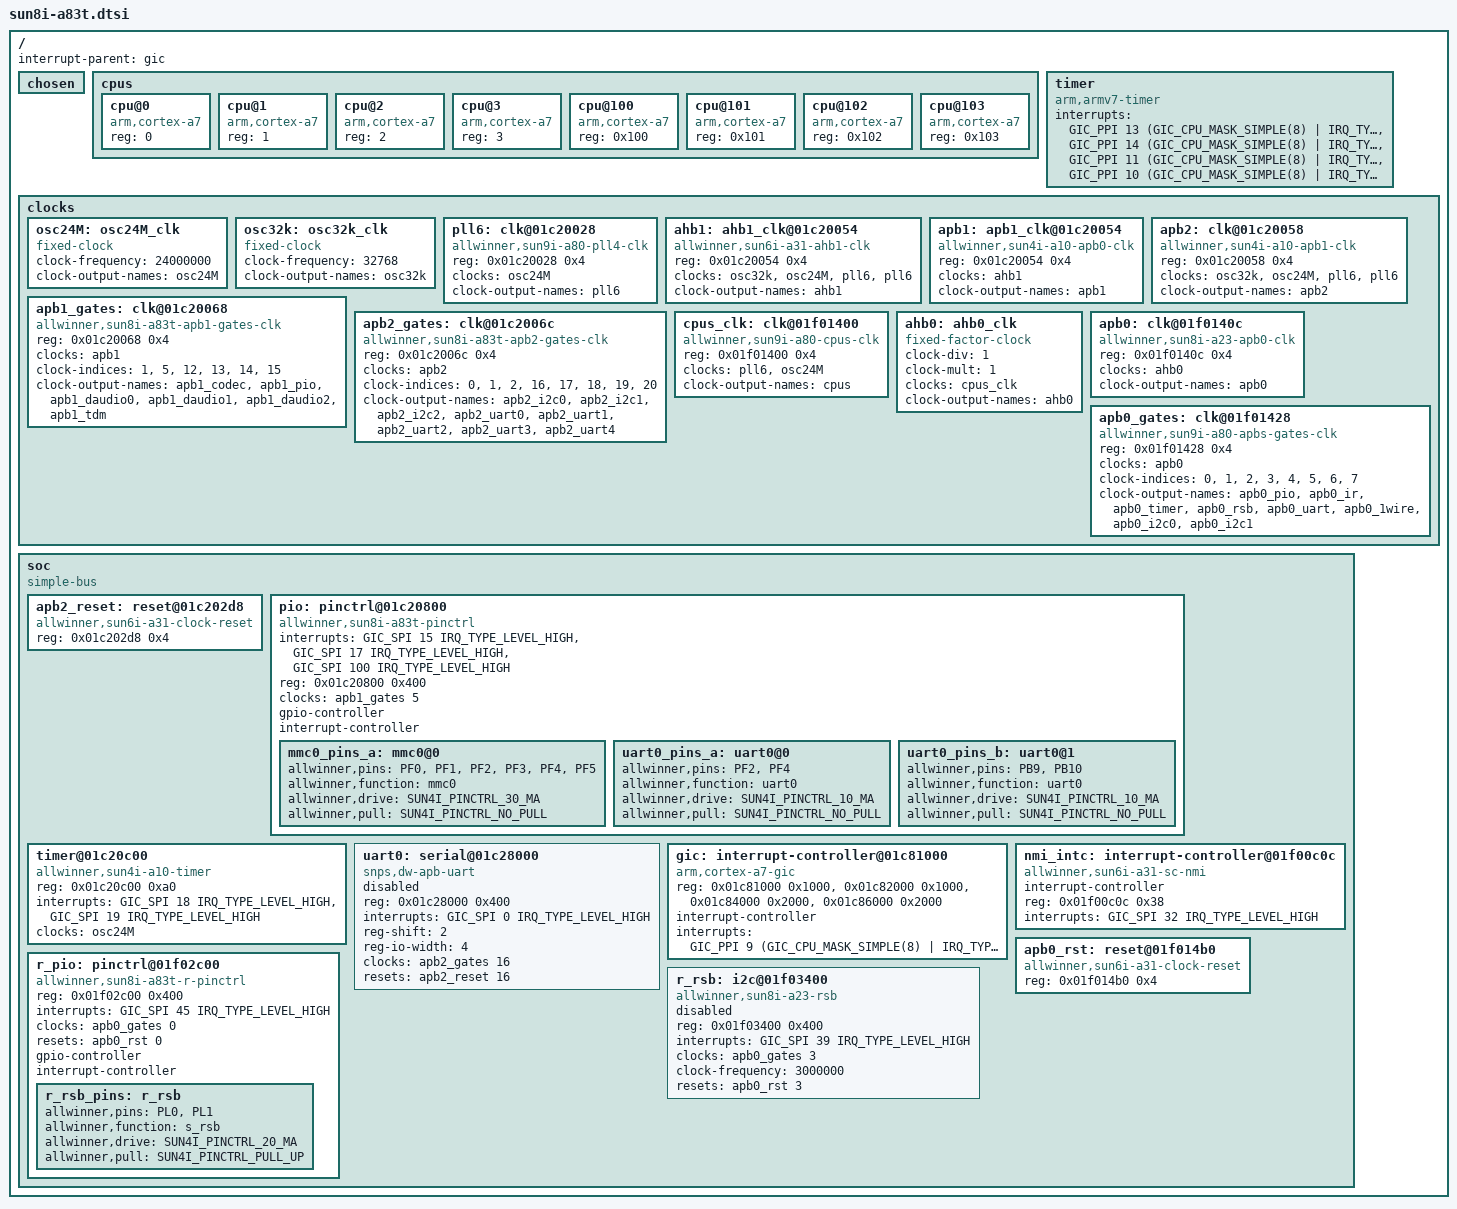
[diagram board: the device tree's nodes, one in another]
/*
 * Copyright 2015 Vishnu Patekar
 *
 * Vishnu Patekar <vishnupatekar0510@gmail.com>
 *
 * This file is dual-licensed: you can use it either under the terms
 * of the GPL or the X11 license, at your option. Note that this dual
 * licensing only applies to this file, and not this project as a
 * whole.
 *
 *  a) This file is free software; you can redistribute it and/or
 *     modify it under the terms of the GNU General Public License as
 *     published by the Free Software Foundation; either version 2 of the
 *     License, or (at your option) any later version.
 *
 *     This file is distributed in the hope that it will be useful,
 *     but WITHOUT ANY WARRANTY; without even the implied warranty of
 *     MERCHANTABILITY or FITNESS FOR A PARTICULAR PURPOSE.  See the
 *     GNU General Public License for more details.
 *
 * Or, alternatively,
 *
 *  b) Permission is hereby granted, free of charge, to any person
 *     obtaining a copy of this software and associated documentation
 *     files (the "Software"), to deal in the Software without
 *     restriction, including without limitation the rights to use,
 *     copy, modify, merge, publish, distribute, sublicense, and/or
 *     sell copies of the Software, and to permit persons to whom the
 *     Software is furnished to do so, subject to the following
 *     conditions:
 *
 *     The above copyright notice and this permission notice shall be
 *     included in all copies or substantial portions of the Software.
 *
 *     THE SOFTWARE IS PROVIDED "AS IS", WITHOUT WARRANTY OF ANY KIND,
 *     EXPRESS OR IMPLIED, INCLUDING BUT NOT LIMITED TO THE WARRANTIES
 *     OF MERCHANTABILITY, FITNESS FOR A PARTICULAR PURPOSE AND
 *     NONINFRINGEMENT. IN NO EVENT SHALL THE AUTHORS OR COPYRIGHT
 *     HOLDERS BE LIABLE FOR ANY CLAIM, DAMAGES OR OTHER LIABILITY,
 *     WHETHER IN AN ACTION OF CONTRACT, TORT OR OTHERWISE, ARISING
 *     FROM, OUT OF OR IN CONNECTION WITH THE SOFTWARE OR THE USE OR
 *     OTHER DEALINGS IN THE SOFTWARE.

 */

#include "skeleton.dtsi"

#include <dt-bindings/interrupt-controller/arm-gic.h>

#include <dt-bindings/pinctrl/sun4i-a10.h>

/ {
	interrupt-parent = <&gic>;

	chosen {
		#address-cells = <1>;
		#size-cells = <1>;
		ranges;
	};

	cpus {
		#address-cells = <1>;
		#size-cells = <0>;

		cpu@0 {
			compatible = "arm,cortex-a7";
			device_type = "cpu";
			reg = <0>;
		};

		cpu@1 {
			compatible = "arm,cortex-a7";
			device_type = "cpu";
			reg = <1>;
		};

		cpu@2 {
			compatible = "arm,cortex-a7";
			device_type = "cpu";
			reg = <2>;
		};

		cpu@3 {
			compatible = "arm,cortex-a7";
			device_type = "cpu";
			reg = <3>;
		};

		cpu@100 {
			compatible = "arm,cortex-a7";
			device_type = "cpu";
			reg = <0x100>;
		};

		cpu@101 {
			compatible = "arm,cortex-a7";
			device_type = "cpu";
			reg = <0x101>;
		};

		cpu@102 {
			compatible = "arm,cortex-a7";
			device_type = "cpu";
			reg = <0x102>;
		};

		cpu@103 {
			compatible = "arm,cortex-a7";
			device_type = "cpu";
			reg = <0x103>;
		};
	};

	timer {
		compatible = "arm,armv7-timer";
		interrupts = <GIC_PPI 13 (GIC_CPU_MASK_SIMPLE(8) | IRQ_TYPE_LEVEL_LOW)>,
			     <GIC_PPI 14 (GIC_CPU_MASK_SIMPLE(8) | IRQ_TYPE_LEVEL_LOW)>,
			     <GIC_PPI 11 (GIC_CPU_MASK_SIMPLE(8) | IRQ_TYPE_LEVEL_LOW)>,
			     <GIC_PPI 10 (GIC_CPU_MASK_SIMPLE(8) | IRQ_TYPE_LEVEL_LOW)>;
	};

	clocks {
		#address-cells = <1>;
		#size-cells = <1>;
		ranges;

		osc24M: osc24M_clk {
			#clock-cells = <0>;
			compatible = "fixed-clock";
			clock-frequency = <24000000>;
			clock-output-names = "osc24M";
		};

		osc32k: osc32k_clk {
			#clock-cells = <0>;
			compatible = "fixed-clock";
			clock-frequency = <32768>;
			clock-output-names = "osc32k";
		};

		pll6: clk@01c20028 {
			#clock-cells = <0>;
			compatible = "allwinner,sun9i-a80-pll4-clk";
			reg = <0x01c20028 0x4>;
			clocks = <&osc24M>;
			clock-output-names = "pll6";
		};

		ahb1: ahb1_clk@01c20054 {
			#clock-cells = <0>;
			compatible = "allwinner,sun6i-a31-ahb1-clk";
			reg = <0x01c20054 0x4>;
			clocks = <&osc32k>, <&osc24M>, <&pll6>, <&pll6>;
			clock-output-names = "ahb1";
		};

		apb1: apb1_clk@01c20054 {
			#clock-cells = <0>;
			compatible = "allwinner,sun4i-a10-apb0-clk";
			reg = <0x01c20054 0x4>;
			clocks = <&ahb1>;
			clock-output-names = "apb1";
		};

		apb2: clk@01c20058 {
			#clock-cells = <0>;
			compatible = "allwinner,sun4i-a10-apb1-clk";
			reg = <0x01c20058 0x4>;
			clocks = <&osc32k>, <&osc24M>, <&pll6>, <&pll6>;
			clock-output-names = "apb2";
		};

		apb1_gates: clk@01c20068 {
			#clock-cells = <1>;
			compatible = "allwinner,sun8i-a83t-apb1-gates-clk";
			reg = <0x01c20068 0x4>;
			clocks = <&apb1>;
			clock-indices = <1>, <5>,
					<12>, <13>,
					<14>, <15>;
			clock-output-names = "apb1_codec", "apb1_pio",
					"apb1_daudio0",	"apb1_daudio1",
					"apb1_daudio2",	"apb1_tdm";
		};

		apb2_gates: clk@01c2006c {
			#clock-cells = <1>;
			compatible = "allwinner,sun8i-a83t-apb2-gates-clk";
			reg = <0x01c2006c 0x4>;
			clocks = <&apb2>;
			clock-indices = <0>, <1>,
					<2>, <16>,
					<17>, <18>,
					<19>, <20>;
			clock-output-names = "apb2_i2c0", "apb2_i2c1",
					"apb2_i2c2", "apb2_uart0",
					"apb2_uart1", "apb2_uart2",
					"apb2_uart3", "apb2_uart4";
		};

		cpus_clk: clk@01f01400 {
			compatible = "allwinner,sun9i-a80-cpus-clk";
			reg = <0x01f01400 0x4>;
			#clock-cells = <0>;
			clocks = <&pll6>, <&osc24M>;
			clock-output-names = "cpus";
		};

		ahb0: ahb0_clk {
			compatible = "fixed-factor-clock";
			#clock-cells = <0>;
			clock-div = <1>;
			clock-mult = <1>;
			clocks = <&cpus_clk>;
			clock-output-names = "ahb0";
		};

		apb0: clk@01f0140c {
			compatible = "allwinner,sun8i-a23-apb0-clk";
			reg = <0x01f0140c 0x4>;
			#clock-cells = <0>;
			clocks = <&ahb0>;
			clock-output-names = "apb0";
		};

		apb0_gates: clk@01f01428 {
			compatible = "allwinner,sun9i-a80-apbs-gates-clk";
			reg = <0x01f01428 0x4>;
			#clock-cells = <1>;
			clocks = <&apb0>;
			clock-indices = <0>, <1>,
					<2>, <3>,
					<4>, <5>,
					<6>, <7>;
			clock-output-names = "apb0_pio", "apb0_ir",
					"apb0_timer", "apb0_rsb",
					"apb0_uart", "apb0_1wire",
					"apb0_i2c0", "apb0_i2c1";
		};
	};

	soc {
		compatible = "simple-bus";
		#address-cells = <1>;
		#size-cells = <1>;
		ranges;

		apb2_reset: reset@01c202d8 {
			#reset-cells = <1>;
			compatible = "allwinner,sun6i-a31-clock-reset";
			reg = <0x01c202d8 0x4>;
		};

		pio: pinctrl@01c20800 {
			compatible = "allwinner,sun8i-a83t-pinctrl";
			interrupts = <GIC_SPI 15 IRQ_TYPE_LEVEL_HIGH>,
				     <GIC_SPI 17 IRQ_TYPE_LEVEL_HIGH>,
				     <GIC_SPI 100 IRQ_TYPE_LEVEL_HIGH>;
			reg = <0x01c20800 0x400>;
			clocks = <&apb1_gates 5>;
			gpio-controller;
			interrupt-controller;
			#interrupt-cells = <3>;
			#gpio-cells = <3>;

			mmc0_pins_a: mmc0@0 {
				allwinner,pins = "PF0", "PF1", "PF2",
						 "PF3", "PF4", "PF5";
				allwinner,function = "mmc0";
				allwinner,drive = <SUN4I_PINCTRL_30_MA>;
				allwinner,pull = <SUN4I_PINCTRL_NO_PULL>;
			};

			uart0_pins_a: uart0@0 {
				allwinner,pins = "PF2", "PF4";
				allwinner,function = "uart0";
				allwinner,drive = <SUN4I_PINCTRL_10_MA>;
				allwinner,pull = <SUN4I_PINCTRL_NO_PULL>;
			};

			uart0_pins_b: uart0@1 {
				allwinner,pins = "PB9", "PB10";
				allwinner,function = "uart0";
				allwinner,drive = <SUN4I_PINCTRL_10_MA>;
				allwinner,pull = <SUN4I_PINCTRL_NO_PULL>;
			};
		};

		timer@01c20c00 {
			compatible = "allwinner,sun4i-a10-timer";
			reg = <0x01c20c00 0xa0>;
			interrupts = <GIC_SPI 18 IRQ_TYPE_LEVEL_HIGH>,
				     <GIC_SPI 19 IRQ_TYPE_LEVEL_HIGH>;
			clocks = <&osc24M>;
		};

		uart0: serial@01c28000 {
			compatible = "snps,dw-apb-uart";
			reg = <0x01c28000 0x400>;
			interrupts = <GIC_SPI 0 IRQ_TYPE_LEVEL_HIGH>;
			reg-shift = <2>;
			reg-io-width = <4>;
			clocks = <&apb2_gates 16>;
			resets = <&apb2_reset 16>;
			status = "disabled";
		};

		gic: interrupt-controller@01c81000 {
			compatible = "arm,cortex-a7-gic", "arm,cortex-a15-gic";
			reg = <0x01c81000 0x1000>,
			      <0x01c82000 0x1000>,
			      <0x01c84000 0x2000>,
			      <0x01c86000 0x2000>;
			interrupt-controller;
			#interrupt-cells = <3>;
			interrupts = <GIC_PPI 9 (GIC_CPU_MASK_SIMPLE(8) | IRQ_TYPE_LEVEL_HIGH)>;
		};

		nmi_intc: interrupt-controller@01f00c0c {
			compatible = "allwinner,sun6i-a31-sc-nmi";
			interrupt-controller;
			#interrupt-cells = <2>;
			reg = <0x01f00c0c 0x38>;
			interrupts = <GIC_SPI 32 IRQ_TYPE_LEVEL_HIGH>;
		};

		apb0_rst: reset@01f014b0 {
			reg = <0x01f014b0 0x4>;
			compatible = "allwinner,sun6i-a31-clock-reset";
			#reset-cells = <1>;
		};

		r_pio: pinctrl@01f02c00 {
			compatible = "allwinner,sun8i-a83t-r-pinctrl";
			reg = <0x01f02c00 0x400>;
			interrupts = <GIC_SPI 45 IRQ_TYPE_LEVEL_HIGH>;
			clocks = <&apb0_gates 0>;
			resets = <&apb0_rst 0>;
			gpio-controller;
			interrupt-controller;
			#interrupt-cells = <3>;
			#address-cells = <1>;
			#size-cells = <0>;
			#gpio-cells = <3>;

			r_rsb_pins: r_rsb {
				allwinner,pins = "PL0", "PL1";
				allwinner,function = "s_rsb";
				allwinner,drive = <SUN4I_PINCTRL_20_MA>;
				allwinner,pull = <SUN4I_PINCTRL_PULL_UP>;
			};
		};

		r_rsb: i2c@01f03400 {
			compatible = "allwinner,sun8i-a23-rsb";
			reg = <0x01f03400 0x400>;
			interrupts = <GIC_SPI 39 IRQ_TYPE_LEVEL_HIGH>;
			clocks = <&apb0_gates 3>;
			clock-frequency = <3000000>;
			resets = <&apb0_rst 3>;
			status = "disabled";
			#address-cells = <1>;
			#size-cells = <0>;
		};
	};
};
